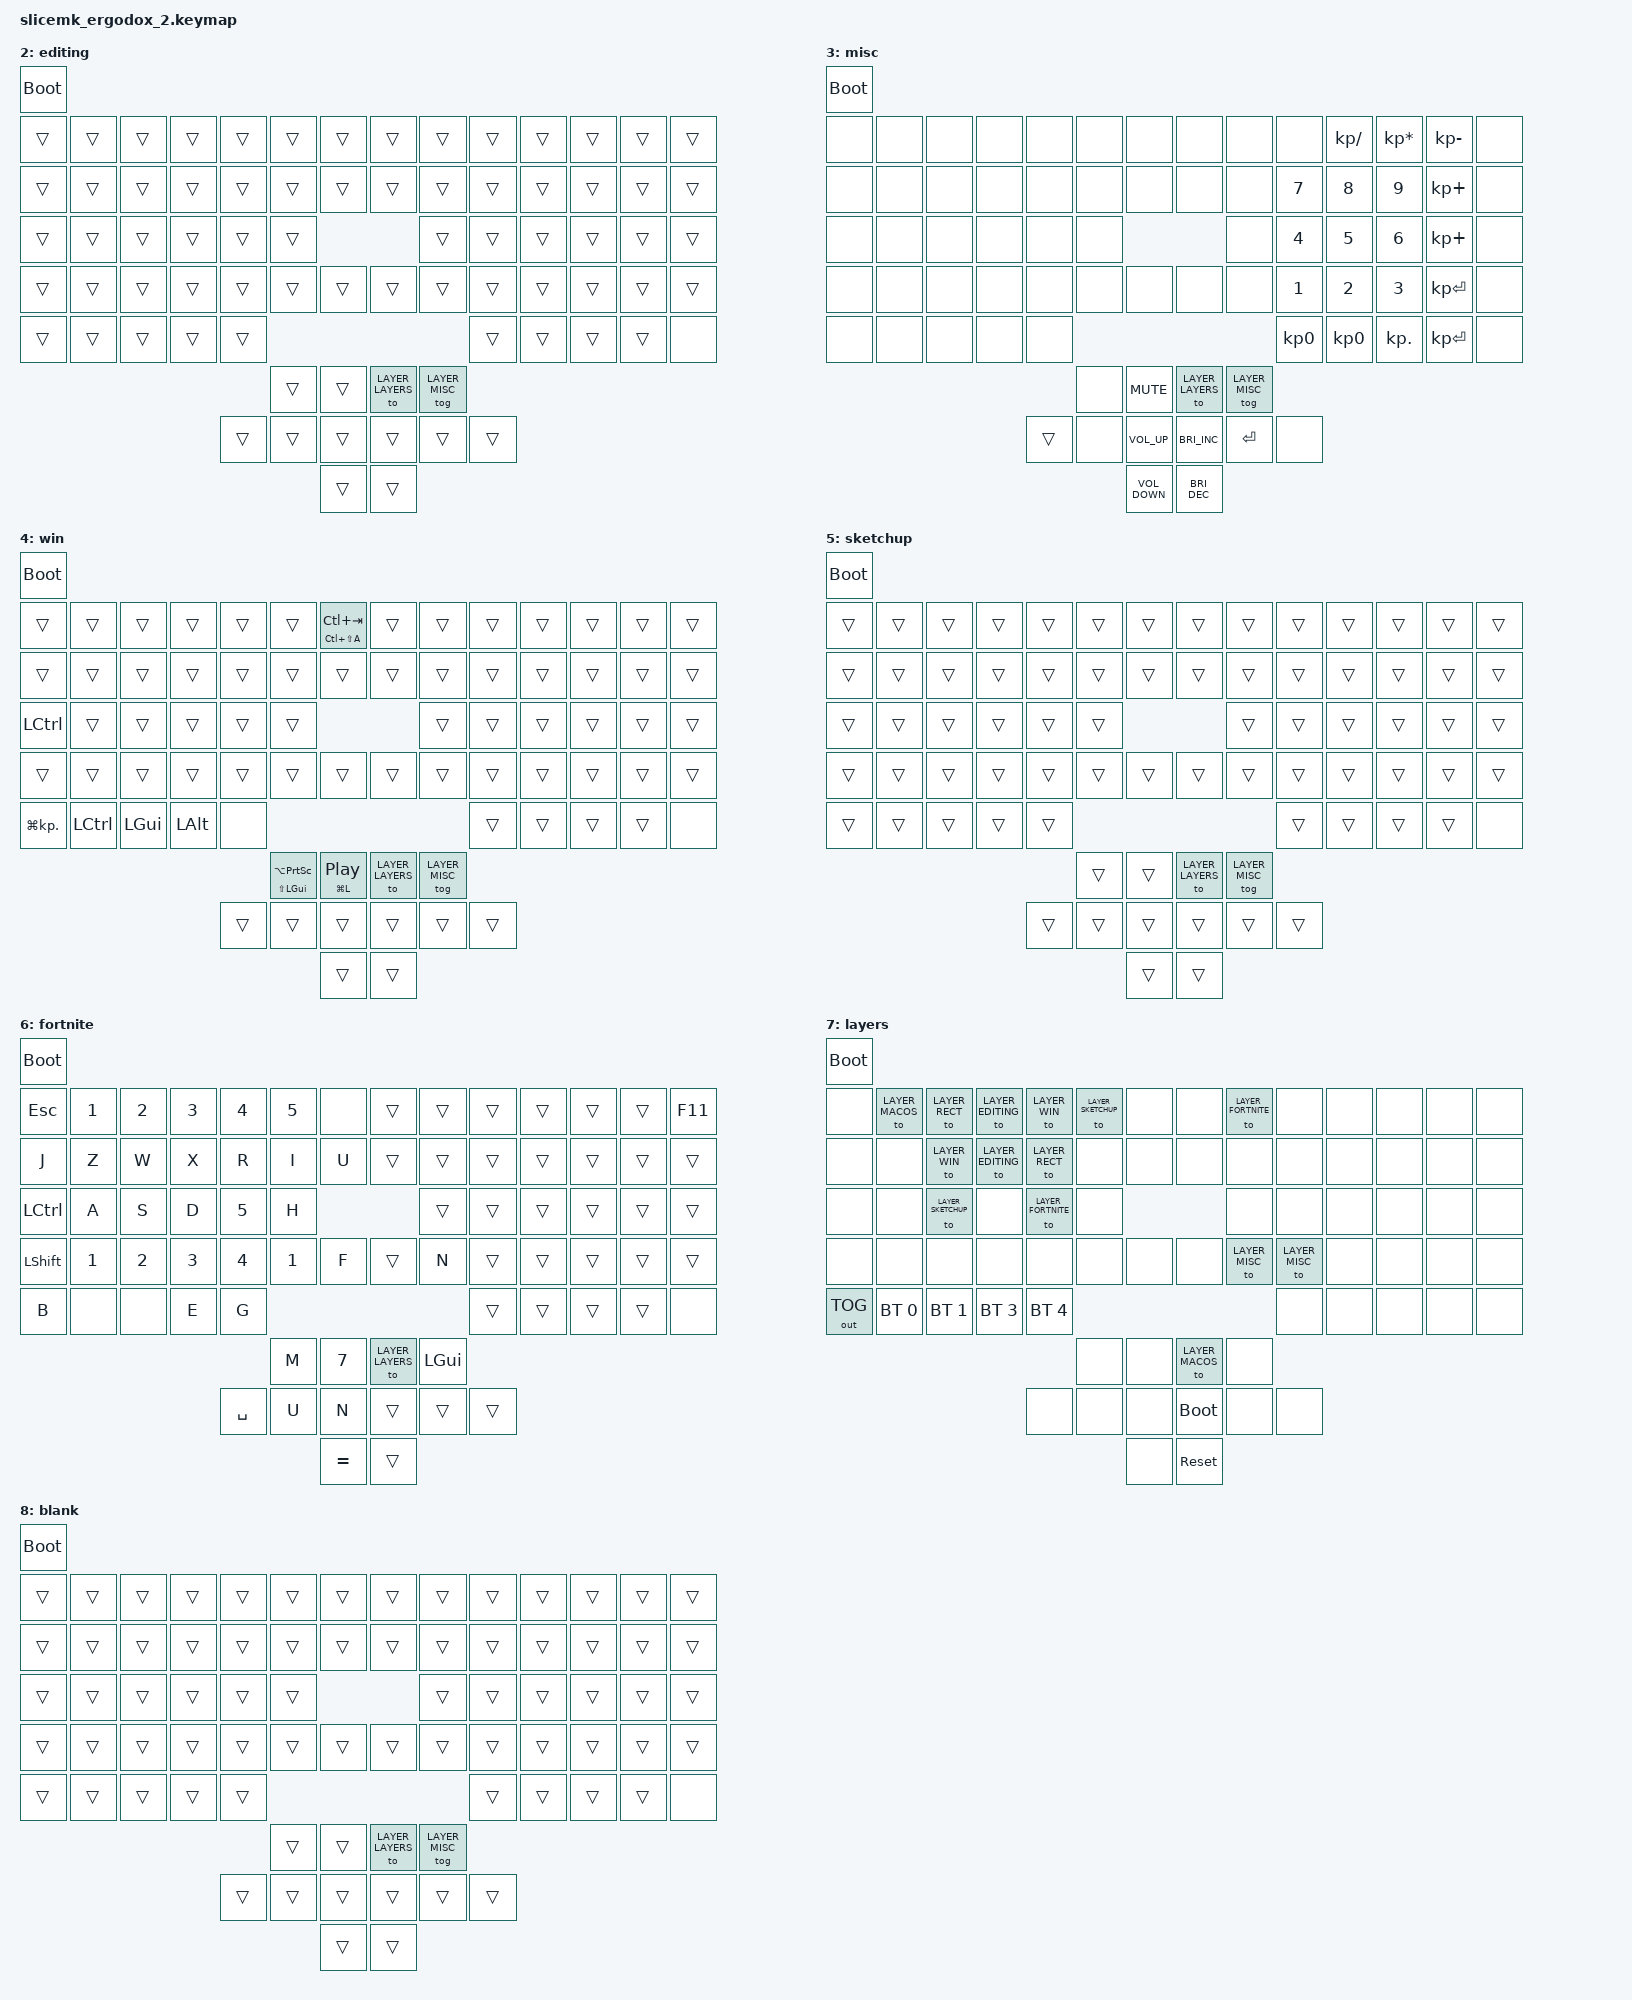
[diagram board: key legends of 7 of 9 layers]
#define LAYER_MACOS 0
#define LAYER_RECT 1
#define LAYER_EDITING 2
#define LAYER_MISC 3
#define LAYER_WIN 4
#define LAYER_SKETCHUP 5
#define LAYER_FORTNITE 6
#define LAYER_LAYERS 7
#define LAYER_SPARE 8

#include <behaviors.dtsi>
#include <dt-bindings/zmk/bt.h>
#include <dt-bindings/zmk/keys.h>
#include <dt-bindings/zmk/outputs.h>
#include <dt-bindings/zmk/pointing.h>
#include <dt-bindings/zmk/rgb.h>
#include "zmk-helpers/helper.h"

/* Global Defaults */
#define MOD_FAKE_TAP_MS 25
#define QUICK_TAP_MS 150
#define ALPHA_TAP_TERM_MS 350 // leaving this high to prevent hold misfires on the alpha keys
#define OTHER_TAP_TERM_MS 300
#define PRIOR_IDLE_MS 167 // calibrated to 10500/63, where 63 is my casual WPM

&mt {
  flavor = "tap-preferred";
  //flavor = "balanced";
  tapping-term-ms = <OTHER_TAP_TERM_MS>;
  quick-tap-ms = <QUICK_TAP_MS>;
  //require-prior-idle-ms = <PRIOR_IDLE_MS>;
};
&lt {
  	tapping-term-ms = <OTHER_TAP_TERM_MS>;
  	quick-tap-ms = <QUICK_TAP_MS>;
    //require-prior-idle-ms = <PRIOR_IDLE_MS>;
	flavor = "tap-preferred";
    bindings = <&kp>, <&kp>;
};

/ {
    behaviors {
        hml: home_row_mod_left {
            compatible = "zmk,behavior-hold-tap";
            #binding-cells = <2>;
            flavor = "balanced";
            require-prior-idle-ms = <150>;
            tapping-term-ms = <280>;
            quick-tap-ms = <175>;
            bindings = <&kp>, <&kp>;
            hold-trigger-key-positions = <8 9 10 11 12 13 14 22 23 24 25 26 27 28 35 36 37 38 39 40 49 50 51 52 53 54 60 61 62 63 64 67 68 72 73 74 76>; // List of keys on the right side of the keyboard
            hold-trigger-on-release;
        };
        hmr: home_row_mod_right {
            compatible = "zmk,behavior-hold-tap";
            #binding-cells = <2>;
            flavor = "balanced";
            require-prior-idle-ms = <150>;
            tapping-term-ms = <280>;
            quick-tap-ms = <175>;
            bindings = <&kp>, <&kp>;
            hold-trigger-key-positions = <1 2 3 4 5 6 7 15 16 17 18 19 2 21 29 30 31 32 33 34 41 42 43 44 45 46 47 55 56 57 58 59 65 66 69 70 71 75>; // List of keys on the left side of the keyboard
            hold-trigger-on-release;
		};
		c_td: custom_tap_dance {
			compatible = "zmk,behavior-tap-dance";
			#binding-cells = <2>;
			tapping-term-ms = <ALPHA_TAP_TERM_MS>;
			bindings = <&kp>, <&kp>;
		};
		c_mt: custom_mod_tap {
			compatible = "zmk,behavior-hold-tap";
			#binding-cells = <2>;
			tapping-term-ms = <ALPHA_TAP_TERM_MS>;
			quick-tap-ms = <QUICK_TAP_MS>;
			require-prior-idle-ms = <PRIOR_IDLE_MS>;
			flavor = "tap-preferred";
			bindings = <&kp>, <&c_td N1 F1>;
		};
		num_mt: num_mod_tap {
   			compatible = "zmk,behavior-hold-tap";
			#binding-cells = <2>;
  			tapping-term-ms = <ALPHA_TAP_TERM_MS>;
  			quick-tap-ms = <QUICK_TAP_MS>;
  			require-prior-idle-ms = <PRIOR_IDLE_MS>;
			flavor = "tap-preferred";
            bindings = <&kp>, <&kp>;
        };
		sh_mt: shift_mod_tap {
   			compatible = "zmk,behavior-hold-tap";
			#binding-cells = <2>;
  			tapping-term-ms = <MOD_FAKE_TAP_MS>;
			//flavor = "balanced";
			flavor = "hold-preferred";
            bindings = <&kp>, <&kp>;
        };

		leader_sys: leader_sys {
			compatible = "zmk,behavior-leader-key";
			#binding-cells = <0>;
            usb { sequence = <U S B>; bindings = <&out OUT_USB>; };
            ble { sequence = <B L E>; bindings = <&out OUT_BLE>; };
            bt0 { sequence = <B N0>; bindings = <&bt BT_SEL 0>; };
            bt1 { sequence = <B N1>; bindings = <&bt BT_SEL 1>; };
            bt2 { sequence = <B N2>; bindings = <&bt BT_SEL 2>; };
            btc { sequence = <C L E A R>; bindings = <&bt BT_CLR>; };
			boot { sequence = <B O O T>; bindings = <&bootloader>; };
            reset { sequence = <R E S E T>; bindings = <&sys_reset>; };
		};
    };
};

/ {
	keymap {
		compatible = "zmk,keymap";
		macos {
			bindings = <
				&bootloader
				&kp ESCAPE          &c_mt EXCL NONE  &mt AT N2    &mt HASH N3  &mt DLLR N4   &mt PERCENT N5 &mt LS(LG(A)) LC(TAB)                          &key_repeat        &mt CARET N6     &mt AMP N7     &mt STAR N8    &mt LPAR N9  &mt RPAR N0     &mt UNDERSCORE MINUS
				&kp TAB             &kp Q            &mt LG(W) W  &kp E        &mt LG(R) R   &mt LG(T) T    &mt TILDE GRAVE                                &mt PLUS EQUAL     &kp Y           &mt LG(U) U    &mt LG(I) I    &kp O        &kp P           &kp BACKSLASH
				&kp LEFT_GUI        &mt LG(A) A      &mt LG(S) S  &kp D        &mt LG(F) F   &kp G                                                                            &kp H           &kp J          &kp K          &mt LG(L) L  &kp SEMICOLON   &kp SINGLE_QUOTE
				&sh_mt LSHIFT &none &mt LG(Z) Z      &mt LG(X) X  &mt LG(C) C  &mt LG(V) V   &mt LG(B) B    &mt KP_LPAR LBKT                               &mt KP_RPAR RBKT   &mt LG(N) N     &kp M          &kp COMMA      &kp PERIOD   &kp SLASH       &sh_mt RSHIFT &none
				&kp LC(LG(SPACE))   &kp LCTRL        &none        &kp LALT     &kp LGUI                                                                                                       &kp LEFT       &kp DOWN       &kp UP       &kp RIGHT       &leader_sys
				                                                                           &mt LS(LG(N2)) LS(LG(N1))   &mt LC(LG(Q)) C_PLAY_PAUSE        &to LAYER_LAYERS    &tog LAYER_MISC
				                                                             &kp BACKSPACE &lt LAYER_RECT DELETE       &kp END                           &kp PAGE_UP         &lt LAYER_EDITING RETURN   &kp SPACE
				                                                                                                       &kp HOME                          &kp PAGE_DOWN
			>;
		};
		rect {
			bindings = <
				&bootloader
				&trans           &kp LC(LS(LA(NUMBER_1))) &kp LC(LS(LA(NUMBER_2))) &kp LC(LS(LA(NUMBER_3))) &kp LC(LS(LA(NUMBER_4))) &trans               &mt LC(LS(A)) LC(TAB) &trans            &trans             &trans                         &trans           &trans              &trans                          &trans
				&trans           &trans                   &kp LC(LA(RETURN))       &trans                   &kp LC(LEFT_SHIFT)       &kp LC(LS(LEFT_ALT)) &trans                &trans            &trans             &trans                         &trans           &trans              &trans                          &trans
				&kp LEFT_CONTROL &trans                   &kp LS(LEFT_ALT)         &trans                   &kp LC(LG(F))            &trans                                                       &kp LC(LEFT_ARROW) &trans                         &kp LC(UP_ARROW) &kp LC(RIGHT_ARROW) &trans                          &trans
				&trans           &trans                   &trans                   &trans                   &trans                   &trans               &trans                &trans            &trans             &trans                         &trans           &trans              &trans                          &trans
				&trans           &trans                   &trans                   &trans                   &trans                                                                                                   &kp LC(LS(LA(LG(LEFT_ARROW)))) &trans           &kp LC(LA(EQUAL))   &kp LC(LS(LA(LG(RIGHT_ARROW)))) &none
				                                                                                                                     &trans               &trans                &to LAYER_LAYERS  &tog LAYER_MISC
				                                                                                            &trans                   &trans               &trans                &kp LC(LA(EQUAL)) &kp LC(LA(RETURN)) &trans
				                                                                                                                                          &trans                &kp LC(LA(MINUS))
			>;
		};
		editing {
			bindings = <
				&bootloader
				&trans &trans &trans &trans &trans &trans &trans &trans           &trans          &trans &trans &trans &trans &trans
				&trans &trans &trans &trans &trans &trans &trans &trans           &trans          &trans &trans &trans &trans &trans
				&trans &trans &trans &trans &trans &trans                         &trans          &trans &trans &trans &trans &trans
				&trans &trans &trans &trans &trans &trans &trans &trans           &trans          &trans &trans &trans &trans &trans
				&trans &trans &trans &trans &trans                                                &trans &trans &trans &trans &none
				                                   &trans &trans &to LAYER_LAYERS &tog LAYER_MISC
				                            &trans &trans &trans &trans           &trans          &trans
				                                          &trans &trans
			>;
		};
		misc {
			bindings = <
				&bootloader
				&none &none &none &none &none  &none &none             &none                &none           &none           &kp KP_DIVIDE   &kp KP_MULTIPLY &kp KP_MINUS &none
				&none &none &none &none &none  &none &none             &none                &none           &kp NUMBER_7    &kp NUMBER_8    &kp NUMBER_9    &kp KP_PLUS  &none
				&none &none &none &none &none  &none                                        &none           &kp NUMBER_4    &kp NUMBER_5    &kp NUMBER_6    &kp KP_PLUS  &none
				&none &none &none &none &none  &none &none             &none                &none           &kp NUMBER_1    &kp NUMBER_2    &kp NUMBER_3    &kp KP_ENTER &none
				&none &none &none &none &none                                                               &kp KP_NUMBER_0 &kp KP_NUMBER_0 &kp KP_DOT      &kp KP_ENTER &none
				                               &none &kp C_MUTE        &to LAYER_LAYERS     &tog LAYER_MISC
				                        &trans &none &kp C_VOLUME_UP   &kp C_BRIGHTNESS_INC &kp RETURN      &none
				                                     &kp C_VOLUME_DOWN &kp C_BRIGHTNESS_DEC
			>;
		};
		win {
			bindings = <
				&bootloader
				&trans           &trans           &trans       &trans       &trans &trans                           &mt LC(LS(A)) LC(TAB)  &trans           &trans          &trans &trans &trans &trans &trans
				&trans           &trans           &trans       &trans       &trans &trans                           &trans                 &trans           &trans          &trans &trans &trans &trans &trans
				&kp LEFT_CONTROL &trans           &trans       &trans       &trans &trans                                                                   &trans          &trans &trans &trans &trans &trans
				&trans           &trans           &trans       &trans       &trans &trans                           &trans                 &trans           &trans          &trans &trans &trans &trans &trans
				&kp LG(KP_DOT)   &kp LEFT_CONTROL &kp LEFT_GUI &kp LEFT_ALT &none                                                                                           &trans &trans &trans &trans &none
				                                                                   &mt LS(LEFT_GUI) LA(PRINTSCREEN) &mt LG(L) C_PLAY_PAUSE &to LAYER_LAYERS &tog LAYER_MISC
				                                                            &trans &trans                           &trans                 &trans           &trans          &trans
				                                                                                                    &trans                 &trans
			>;
		};
		sketchup {
			bindings = <
				&bootloader
				&trans &trans &trans &trans &trans &trans &trans &trans           &trans          &trans &trans &trans &trans &trans
				&trans &trans &trans &trans &trans &trans &trans &trans           &trans          &trans &trans &trans &trans &trans
				&trans &trans &trans &trans &trans &trans                         &trans          &trans &trans &trans &trans &trans
				&trans &trans &trans &trans &trans &trans &trans &trans           &trans          &trans &trans &trans &trans &trans
				&trans &trans &trans &trans &trans                                                &trans &trans &trans &trans &none
				                                   &trans &trans &to LAYER_LAYERS &tog LAYER_MISC
				                            &trans &trans &trans &trans           &trans          &trans
				                                          &trans &trans
			>;
		};
		fortnite {
			bindings = <
				&bootloader
				&kp ESCAPE       &kp NUMBER_1 &kp NUMBER_2 &kp NUMBER_3 &kp NUMBER_4 &kp NUMBER_5 &none        &trans           &trans       &trans &trans &trans &trans &kp F11
				&kp J            &kp Z        &kp W        &kp X        &kp R        &kp I        &kp U        &trans           &trans       &trans &trans &trans &trans &trans
				&kp LEFT_CONTROL &kp A        &kp S        &kp D        &kp NUMBER_5 &kp H                                      &trans       &trans &trans &trans &trans &trans
				&kp LEFT_SHIFT   &kp NUMBER_1 &kp NUMBER_2 &kp NUMBER_3 &kp NUMBER_4 &kp NUMBER_1 &kp F        &trans           &kp N        &trans &trans &trans &trans &trans
				&kp B            &none        &none        &kp E        &kp G                                                                &trans &trans &trans &trans &none
				                                                                     &kp M        &kp NUMBER_7 &to LAYER_LAYERS &kp LEFT_GUI
				                                                        &kp SPACE    &kp U        &kp N        &trans           &trans       &trans
				                                                                                  &kp EQUAL    &trans
			>;
		};
		layers {
			bindings = <
				&bootloader
				&none        &to LAYER_MACOS &to LAYER_RECT     &to LAYER_EDITING &to LAYER_WIN      &to LAYER_SKETCHUP &none &none           &to LAYER_FORTNITE &none          &none &none &none &none
				&none        &none           &to LAYER_WIN      &to LAYER_EDITING &to LAYER_RECT     &none              &none &none           &none              &none          &none &none &none &none
				&none        &none           &to LAYER_SKETCHUP &none             &to LAYER_FORTNITE &none                                    &none              &none          &none &none &none &none
				&none        &none           &none              &none             &none              &none              &none &none           &to LAYER_MISC     &to LAYER_MISC &none &none &none &none
				&out OUT_TOG &bt BT_SEL 0    &bt BT_SEL 1       &bt BT_SEL 3      &bt BT_SEL 4                                                                   &none          &none &none &none &none
				                                                                                     &none              &none &to LAYER_MACOS &none
				                                                                  &none              &none              &none &bootloader     &none              &none
				                                                                                                        &none &sys_reset
			>;
		};
		blank {
			bindings = <
				&bootloader
				&trans &trans &trans &trans &trans &trans &trans &trans           &trans          &trans &trans &trans &trans &trans
				&trans &trans &trans &trans &trans &trans &trans &trans           &trans          &trans &trans &trans &trans &trans
				&trans &trans &trans &trans &trans &trans                         &trans          &trans &trans &trans &trans &trans
				&trans &trans &trans &trans &trans &trans &trans &trans           &trans          &trans &trans &trans &trans &trans
				&trans &trans &trans &trans &trans                                                &trans &trans &trans &trans &none
				                                   &trans &trans &to LAYER_LAYERS &tog LAYER_MISC
				                            &trans &trans &trans &trans           &trans          &trans
				                                          &trans &trans
			>;
		};
	};
};
